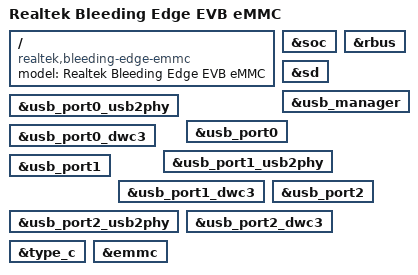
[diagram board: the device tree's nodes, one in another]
// SPDX-License-Identifier: (GPL-2.0-or-later OR BSD-2-Clause)
/*
 * Copyright (c) 2020 Realtek Semiconductor Corp.
 */

/dts-v1/;

#include "rtd1619b-bleedingedge.dtsi"

/ {
	compatible = "realtek,bleeding-edge-emmc", "realtek,rtd1619b";
	model = "Realtek Bleeding Edge EVB eMMC";
};

&soc {
	bootph-all;
};

&rbus {
	bootph-all;
};

&sd {
	bootph-all;
	status = "okay";
};

&usb_manager {
	bootph-all;
};

&usb_port0_usb2phy {
	bootph-all;
};

&usb_port0 {
	bootph-all;
};

&usb_port0_dwc3 {
	bootph-all;
};

&usb_port1_usb2phy {
	bootph-all;
};

&usb_port1 {
	bootph-all;
};

&usb_port1_dwc3 {
	bootph-all;
};

&usb_port2_usb2phy {
	bootph-all;
};

&usb_port2 {
	bootph-all;
};

&usb_port2_dwc3 {
	bootph-all;
};

&type_c {
	bootph-all;
};

&emmc {
	bootph-all;
};
